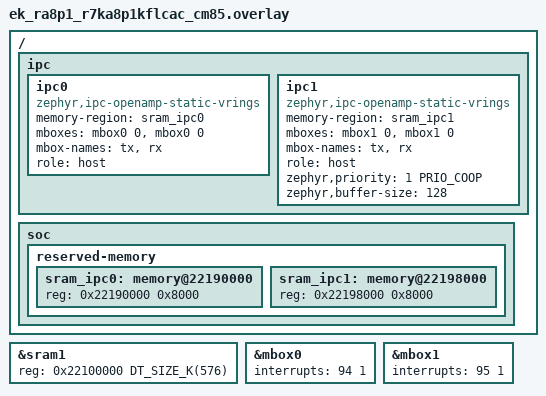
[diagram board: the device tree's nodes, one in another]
/*
 * Copyright (c) 2025-2026 Renesas Electronics Corporation
 * SPDX-License-Identifier: Apache-2.0
 */

#include <zephyr/dt-bindings/ipc_service/static_vrings.h>

/ {
	ipc {
		ipc0: ipc0 {
			compatible = "zephyr,ipc-openamp-static-vrings";
			memory-region = <&sram_ipc0>;
			mboxes = <&mbox0 0>, <&mbox0 0>;
			mbox-names = "tx", "rx";
			role = "host";
			status = "okay";
		};

		ipc1: ipc1 {
			compatible = "zephyr,ipc-openamp-static-vrings";
			memory-region = <&sram_ipc1>;
			mboxes = <&mbox1 0>, <&mbox1 0>;
			mbox-names = "tx", "rx";
			role = "host";
			zephyr,priority = <1 PRIO_COOP>;
			zephyr,buffer-size = <128>;
			status = "okay";
		};
	};

	soc {
		/* Define shared memory regions for IPC */
		reserved-memory {
			#address-cells = <1>;
			#size-cells = <1>;

			sram_ipc0: memory@22190000 {
				reg = <0x22190000 0x8000>;
			};

			sram_ipc1: memory@22198000 {
				reg = <0x22198000 0x8000>;
			};
		};
	};
};

/* Redefine sram size for CPU1 */
&sram1 {
	reg = <0x22100000 DT_SIZE_K(576)>;
};

&mbox0 {
	interrupts = <94 1>;
	status = "okay";
};

&mbox1 {
	interrupts = <95 1>;
	status = "okay";
};
